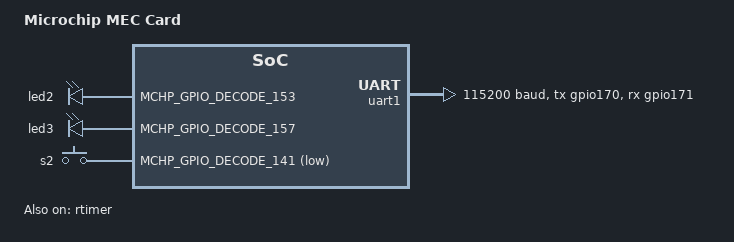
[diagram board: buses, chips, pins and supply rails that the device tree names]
/*
 * Copyright (c) 2025, Microchip Technology Inc.
 *
 * SPDX-License-Identifier: Apache-2.0
 */

/dts-v1/;

#include <microchip/mec/mec5_mec1753qsz.dtsi>
#include <microchip/mec/mec5/mec175x-pinctrl.dtsi>

/ {
	model = "Microchip MEC Card";
	compatible = "microchip,ec_card-mec1753_qsz";

	chosen {
		zephyr,sram = &sram0;
		zephyr,flash = &flash0;
		zephyr,console = &uart1;
		zephyr,shell-uart = &uart1;
	};

	leds {
        compatible = "gpio-leds";
        led2: led_2 {
            gpios = <MCHP_GPIO_DECODE_153 GPIO_ACTIVE_HIGH>;
        };

		led3: led_3 {
            gpios = <MCHP_GPIO_DECODE_157 GPIO_ACTIVE_HIGH>;
        };
    };

	btns {
		compatible = "gpio-keys";
		s2: btn_1 {
			gpios = <MCHP_GPIO_DECODE_141 GPIO_ACTIVE_LOW>;
		};
	};

	power-states {
		idle: idle {
			compatible = "zephyr,power-state";
			power-state-name = "suspend-to-idle";
			min-residency-us = <100000>;
		};

		suspend_to_ram: suspend_to_ram {
			compatible = "zephyr,power-state";
			power-state-name = "suspend-to-ram";
			min-residency-us = <200000>;
		};
	};
};

&cpu0 {
	clock-frequency = <96000000>;
	status = "okay";
	cpu-power-states = <&idle &suspend_to_ram>;
};

/* Disable ARM SysTick kernel timer driver */
&systick {
	status = "disabled";
};

/* Enable MCHP kernel timer driver using 32KHz RTOS timer and 1MHz basic timer */
&rtimer {
	status = "okay";
};

&uart1 {
	compatible = "microchip,xec-uart";
	status = "okay";
	clock-frequency = <1843200>;
	current-speed = <115200>;
	pinctrl-0 = <&uart1_tx_gpio170 &uart1_rx_gpio171>;
	pinctrl-names = "default";
};
